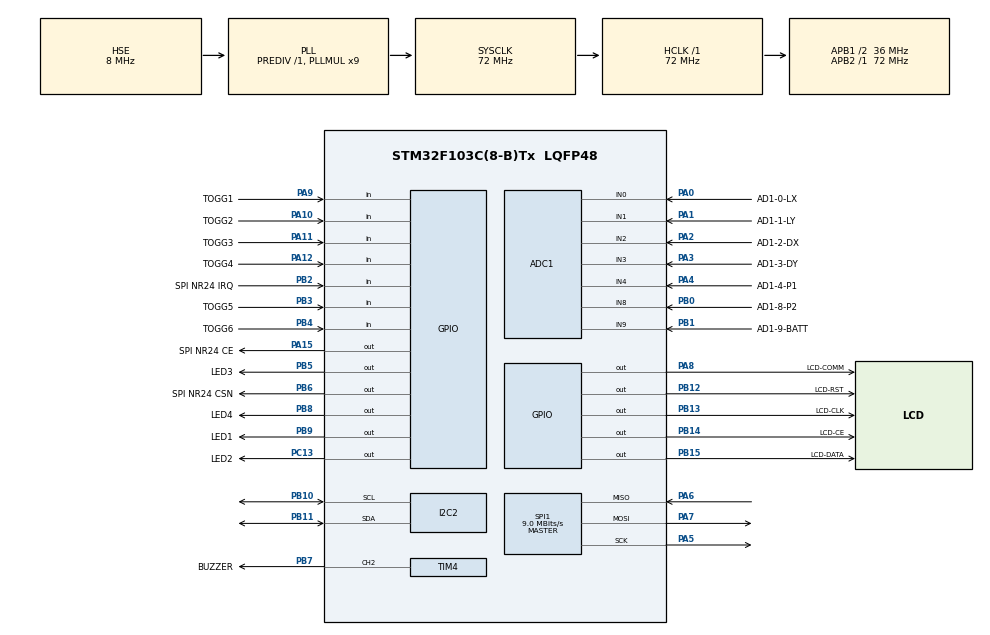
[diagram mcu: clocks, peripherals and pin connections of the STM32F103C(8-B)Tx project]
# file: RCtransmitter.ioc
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ADC1.Channel-0\#ChannelRegularConversion=ADC_CHANNEL_0
ADC1.Channel-1\#ChannelRegularConversion=ADC_CHANNEL_1
ADC1.Channel-2\#ChannelRegularConversion=ADC_CHANNEL_2
ADC1.Channel-3\#ChannelRegularConversion=ADC_CHANNEL_3
ADC1.Channel-4\#ChannelRegularConversion=ADC_CHANNEL_4
ADC1.Channel-5\#ChannelRegularConversion=ADC_CHANNEL_8
ADC1.Channel-6\#ChannelRegularConversion=ADC_CHANNEL_9
ADC1.ContinuousConvMode=ENABLE
ADC1.NbrOfConversion=7
ADC1.NbrOfConversionFlag=1
ADC1.Rank-0\#ChannelRegularConversion=1
ADC1.Rank-1\#ChannelRegularConversion=2
ADC1.Rank-2\#ChannelRegularConversion=3
ADC1.Rank-3\#ChannelRegularConversion=4
ADC1.Rank-4\#ChannelRegularConversion=5
ADC1.Rank-5\#ChannelRegularConversion=6
ADC1.Rank-6\#ChannelRegularConversion=7
ADC1.SamplingTime-0\#ChannelRegularConversion=ADC_SAMPLETIME_13CYCLES_5
ADC1.SamplingTime-1\#ChannelRegularConversion=ADC_SAMPLETIME_13CYCLES_5
ADC1.SamplingTime-2\#ChannelRegularConversion=ADC_SAMPLETIME_13CYCLES_5
ADC1.SamplingTime-3\#ChannelRegularConversion=ADC_SAMPLETIME_13CYCLES_5
ADC1.SamplingTime-4\#ChannelRegularConversion=ADC_SAMPLETIME_13CYCLES_5
ADC1.SamplingTime-5\#ChannelRegularConversion=ADC_SAMPLETIME_13CYCLES_5
ADC1.SamplingTime-6\#ChannelRegularConversion=ADC_SAMPLETIME_13CYCLES_5
ADC1.master=1
Dma.ADC1.0.Direction=DMA_PERIPH_TO_MEMORY
Dma.ADC1.0.Instance=DMA1_Channel1
Dma.ADC1.0.MemDataAlignment=DMA_MDATAALIGN_HALFWORD
Dma.ADC1.0.MemInc=DMA_MINC_ENABLE
Dma.ADC1.0.Mode=DMA_CIRCULAR
Dma.ADC1.0.PeriphDataAlignment=DMA_PDATAALIGN_HALFWORD
Dma.ADC1.0.PeriphInc=DMA_PINC_DISABLE
Dma.ADC1.0.Priority=DMA_PRIORITY_HIGH
Dma.Request0=ADC1
I2C2.I2C_Mode=I2C_Standard
Mcu.Family=STM32F1
Mcu.Name=STM32F103C(8-B)Tx
Mcu.Package=LQFP48
NVIC.DMA1_Channel1_IRQn=true\:0\:0\:false\:false\:true\:false\:true
NVIC.PriorityGroup=NVIC_PRIORITYGROUP_4
PA0-WKUP.GPIO_Label=AD1-0-LX
PA0-WKUP.Signal=ADCx_IN0
PA1.GPIO_Label=AD1-1-LY
PA1.Signal=ADCx_IN1
PA10.GPIO_Label=TOGG2
PA10.GPIO_PuPd=GPIO_PULLUP
PA10.Signal=GPIO_Input
PA11.GPIO_Label=TOGG3
PA11.GPIO_PuPd=GPIO_PULLUP
PA11.Signal=GPIO_Input
PA12.GPIO_Label=TOGG4
PA12.GPIO_PuPd=GPIO_PULLUP
PA12.Signal=GPIO_Input
PA13.Mode=Serial_Wire
PA13.Signal=SYS_JTMS-SWDIO
PA14.Mode=Serial_Wire
PA14.Signal=SYS_JTCK-SWCLK
PA15.GPIO_Label=SPI NR24 CE
PA15.Signal=GPIO_Output
PA2.GPIO_Label=AD1-2-DX
PA2.Signal=ADCx_IN2
PA3.GPIO_Label=AD1-3-DY
PA3.Signal=ADCx_IN3
PA4.GPIO_Label=AD1-4-P1
PA4.Signal=ADCx_IN4
PA5.Mode=Full_Duplex_Master
PA5.Signal=SPI1_SCK
PA6.Mode=Full_Duplex_Master
PA6.Signal=SPI1_MISO
PA7.Mode=Full_Duplex_Master
PA7.Signal=SPI1_MOSI
PA8.GPIO_Label=LCD-COMM
PA8.GPIO_Speed=GPIO_SPEED_FREQ_HIGH
PA8.Signal=GPIO_Output
PA9.GPIO_Label=TOGG1
PA9.GPIO_PuPd=GPIO_PULLUP
PA9.Signal=GPIO_Input
PB0.GPIO_Label=AD1-8-P2
PB0.Signal=ADCx_IN8
PB1.GPIO_Label=AD1-9-BATT
PB1.Signal=ADCx_IN9
PB10.Mode=I2C
PB10.Signal=I2C2_SCL
PB11.Mode=I2C
PB11.Signal=I2C2_SDA
PB12.GPIO_Label=LCD-RST
PB12.Signal=GPIO_Output
PB13.GPIO_Label=LCD-CLK
PB13.GPIO_Speed=GPIO_SPEED_FREQ_HIGH
PB13.Signal=GPIO_Output
PB14.GPIO_Label=LCD-CE
PB14.Signal=GPIO_Output
PB15.GPIO_Label=LCD-DATA
PB15.GPIO_Speed=GPIO_SPEED_FREQ_HIGH
PB15.Signal=GPIO_Output
PB2.GPIO_Label=SPI NR24 IRQ
PB2.Signal=GPIO_Input
PB3.GPIO_Label=TOGG5
PB3.GPIO_PuPd=GPIO_PULLUP
PB3.Signal=GPIO_Input
PB4.GPIO_Label=TOGG6
PB4.GPIO_PuPd=GPIO_PULLUP
PB4.Signal=GPIO_Input
PB5.GPIO_Label=LED3
PB5.Signal=GPIO_Output
PB6.GPIO_Label=SPI NR24 CSN
PB6.Signal=GPIO_Output
PB7.GPIO_Label=BUZZER
PB7.Signal=S_TIM4_CH2
PB8.GPIO_Label=LED4
PB8.Signal=GPIO_Output
PB9.GPIO_Label=LED1
PB9.Signal=GPIO_Output
PC13-TAMPER-RTC.GPIO_Label=LED2
PC13-TAMPER-RTC.Signal=GPIO_Output
PD0-OSC_IN.Mode=HSE-External-Oscillator
PD0-OSC_IN.Signal=RCC_OSC_IN
PD1-OSC_OUT.Mode=HSE-External-Oscillator
PD1-OSC_OUT.Signal=RCC_OSC_OUT
ProjectManager.HeapSize=0x200
ProjectManager.StackSize=0x400
ProjectManager.TargetToolchain=STM32CubeIDE
RCC.ADCPresc=RCC_ADCPCLK2_DIV6
RCC.AHBFreq_Value=72000000
RCC.APB1CLKDivider=RCC_HCLK_DIV2
RCC.APB1Freq_Value=36000000
RCC.APB1TimFreq_Value=72000000
RCC.APB2Freq_Value=72000000
RCC.APB2TimFreq_Value=72000000
RCC.HCLKFreq_Value=72000000
RCC.PLLMUL=RCC_PLL_MUL9
RCC.PLLSourceVirtual=RCC_PLLSOURCE_HSE
RCC.SYSCLKFreq_VALUE=72000000
RCC.SYSCLKSource=RCC_SYSCLKSOURCE_PLLCLK
RCC.USBFreq_Value=72000000
SH.ADCx_IN0.0=ADC1_IN0,IN0
SH.ADCx_IN1.0=ADC1_IN1,IN1
SH.ADCx_IN2.0=ADC1_IN2,IN2
SH.ADCx_IN3.0=ADC1_IN3,IN3
SH.ADCx_IN4.0=ADC1_IN4,IN4
SH.ADCx_IN8.0=ADC1_IN8,IN8
SH.ADCx_IN9.0=ADC1_IN9,IN9
SH.S_TIM4_CH2.0=TIM4_CH2,PWM Generation2 CH2
SPI1.BaudRatePrescaler=SPI_BAUDRATEPRESCALER_8
SPI1.CRCCalculation=SPI_CRCCALCULATION_ENABLE
SPI1.CalculateBaudRate=9.0 MBits/s
SPI1.Direction=SPI_DIRECTION_2LINES
SPI1.Mode=SPI_MODE_MASTER
SPI1.VirtualType=VM_MASTER
TIM4.Channel-PWM\ Generation2\ CH2=TIM_CHANNEL_2
TIM4.Period=5000
TIM4.Prescaler=9
TIM4.Pulse-PWM\ Generation2\ CH2=800
board=custom

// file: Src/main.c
/* USER CODE BEGIN Header */
/**
  ******************************************************************************
  * @file           : main.c
  * @brief          : Main program body
  ******************************************************************************
  * @attention
  *
  * <h2><center>&copy; Copyright (c) 2019 STMicroelectronics.
  * All rights reserved.</center></h2>
  *
  * This software component is licensed by ST under BSD 3-Clause license,
  * the "License"; You may not use this file except in compliance with the
  * License. You may obtain a copy of the License at:
  *                        opensource.org/licenses/BSD-3-Clause
  *
  ******************************************************************************
  */
/* USER CODE END Header */

#include "main.h"

/* USER CODE BEGIN Includes */
#include "nokia5110_LCD.h"
#include "nrf24.h"
#include "mcp23017.h"
#include "LCDprints.h"
/* USER CODE END Includes */

ADC_HandleTypeDef hadc1;
DMA_HandleTypeDef hdma_adc1;

I2C_HandleTypeDef hi2c2;

SPI_HandleTypeDef hspi1;

TIM_HandleTypeDef htim4;

/* USER CODE BEGIN PV */
uint32_t test1;
uint32_t test2;
uint32_t test3;
uint32_t test4;
uint32_t wifiOK;

uint32_t watch1,watch2,watch3,watch4,watch5,watch6;

char stringlcdBuffer[20];
uint16_t adcDataArray[7];

//MCP23017
MCP23017str	MCP23017DataStr;

//NRF24
uint8_t nRF24_payloadTX[32]; //TX buffer
uint8_t nRF24_payloadRX[32]; //RX buffer
const uint8_t nRF24_ADDR[3] = {5, 3, 5 }; //Address
uint8_t RXstpaketov=0;

uint32_t MainInitDoneFlag=0;
struct FlashDatastruct FlashDataDefault; //Default constant embedded in Code
struct FlashDatastruct FlashDataFlash;  //Constants read from Flash
struct FlashDatastruct FlashDataActive; //Active constants

struct DroneDataStruct DroneDataActive;
struct DroneDataStruct DroneDataFlash;
struct DroneDataStruct DroneDataTemp;
struct DroneDataStruct DroneDataInput;

float DroneTuneStep=1.0;
uint32_t DroneTuneStepInt=1;

//LCD MENUS
MenuLvL CurrentLvl;
LCDScreen CurrentScreen;
CursorPositions CurrentCursorPos;

//Buttons to move through screens, move cursor and change menu lvl
uint32_t MenuPlus,MenuMinus;
uint32_t CursorUp,CursorDown;
uint32_t ValuePlus,ValueMinus;
uint32_t LvLUp,LvlDown;

extern uint32_t CommShtdownnrf24;
extern uint8_t MSGParameterTX;
extern uint8_t MSGCommTX;

/* USER CODE END PV */

void SystemClock_Config(void);
static void MX_GPIO_Init(void);
static void MX_DMA_Init(void);
static void MX_ADC1_Init(void);
static void MX_SPI1_Init(void);
static void MX_I2C2_Init(void);
static void MX_TIM4_Init(void);

int main(void)
{
  /* USER CODE BEGIN 1 */
	//test timings DWT counter
	CoreDebug->DEMCR |= CoreDebug_DEMCR_TRCENA_Msk;
	DWT->CYCCNT = 0;
	DWT->CTRL |= 1;
  /* USER CODE END 1 */

  /* MCU Configuration--------------------------------------------------------*/

  /* Reset of all peripherals, Initializes the Flash interface and the Systick. */
  HAL_Init();

  /* Configure the system clock */
  SystemClock_Config();

  /* Initialize all configured peripherals */
  MX_GPIO_Init();
  MX_DMA_Init();
  MX_ADC1_Init();
  MX_SPI1_Init();
  MX_I2C2_Init();
  MX_TIM4_Init();
  /* USER CODE BEGIN 2 */

  HAL_ADCEx_Calibration_Start(&hadc1);
  HAL_ADC_Start_DMA(&hadc1,adcDataArray, 7);

  //DEFAULT FLASH CONSTANTS
  FlashDataDefault.controlData=CONTROLWORD;
  FlashDataDefault.LCD_contrast=0xB8;
  FlashDataDefault.LjoyXtrim=0;
  FlashDataDefault.LjoyYtrim=0;
  FlashDataDefault.RjoyXtrim=0;
  FlashDataDefault.RjoyYtrim=0;

  if( CheckFlashData(FLASHCONSTADDR) == CONTROLWORD ) //Check if any Data is present
  {
	  //Read Data and Save parameters into ACTIVE structure
	  ReadFlashData(FLASHCONSTADDR, &FlashDataActive);

  }
  else
  {
	  //Write default values into Flash, Read back data into Active Structure
	  WriteFlashData(FLASHCONSTADDR, &FlashDataDefault);
	  ReadFlashData(FLASHCONSTADDR, &FlashDataActive);
  }

  //Lightshow
  LED1ON;
  LED2ON;
  LED3ON;
  LED4ON;
  HAL_Delay(1000);
  LED1OFF;
  LED2OFF;
  LED3OFF;
  LED4OFF;

  //default LCD
  CurrentLvl=LVL0;
  CurrentScreen=MainScreen;
  CurrentCursorPos=Line0;

  //lcd init pins
  LCD_setRST(LCD_RST_GPIO_Port, LCD_RST_Pin);
  LCD_setDC(LCD_COMM_GPIO_Port, LCD_COMM_Pin);
  LCD_setCE(LCD_CE_GPIO_Port, LCD_CE_Pin);
  LCD_setDIN(LCD_DATA_GPIO_Port, LCD_DATA_Pin);
  LCD_setCLK(LCD_CLK_GPIO_Port, LCD_CLK_Pin);

  LCD_init(&FlashDataActive); //6 lines 15 characters max per line (0,0), (0,1), (0,2), (0,3), (0,4), (0,5) line starts

  //NRF24INIT
  SPI1->CR1|=SPI_CR1_SPE; //enable SPI

  nRF24_CE_L(); // RX/TX disabled

  wifiOK=nRF24_Check();

  nRF24_Init(); //Default init

  // Disable ShockBurst for all RX pipes
  nRF24_DisableAA(0xFF);

  // Set RF channel
  nRF24_SetRFChannel(15); //2400Mhz + 15Mhz

  // Set data rate
  nRF24_SetDataRate(nRF24_DR_250kbps);

  // Set CRC scheme
  nRF24_SetCRCScheme(nRF24_CRC_1byte);

  // Set address width, its common for all pipes (RX and TX)
  nRF24_SetAddrWidth(3);

  nRF24_SetAddr(nRF24_PIPE1, nRF24_ADDR); // program address for RX pipe #1
  nRF24_SetRXPipe(nRF24_PIPE1, nRF24_AA_OFF, 6); // Auto-ACK: disabled, payload length: 6 bytes

  nRF24_SetAddr(nRF24_PIPETX, nRF24_ADDR); // program TX address

  // Set TX power
  nRF24_SetTXPower(nRF24_TXPWR_18dBm);

  // Set operational mode (PTX == transmitter)
  nRF24_SetOperationalMode(nRF24_MODE_TX);

  // Clear any pending IRQ flags
  nRF24_ClearIRQFlags();

  // Wake the transceiver
  nRF24_SetPowerMode(nRF24_PWR_UP);

  //MCP23017 intit
  mcp23017_init(&hi2c2,MCP23017_ADDRESS_20);

  MainInitDoneFlag=1;

  /* USER CODE END 2 */

  /* Infinite loop */
  /* USER CODE BEGIN WHILE */
  while (1)
  {

	  if(MenuPlus)//Menu PLUS------------------------------------------------------------------------------------------------------------------------
	  {
	  	  LCD_clrScr();

	  	  switch(CurrentScreen)
	  	  {
	  	  	  case MainScreen:{CurrentScreen=MenuScreen1;}break;
	  	  	  case MenuScreen1:{CurrentScreen=TestScreen1;}break;
	  	  	  case TestScreen1:{CurrentScreen=MainScreen;}break;

	  	  	  case ButtonScreen1:{CurrentScreen=ButtonScreen2;}break;
	  	  	  case ButtonScreen2:{CurrentScreen=ButtonScreen3;}break;
	  	  	  case ButtonScreen3:{CurrentScreen=ButtonScreen1;}break;

	  	  	  case Param1TuneScreen:{CurrentScreen=Param2TuneScreen;}break;
	  	  	  case Param2TuneScreen:{CurrentScreen=Param3TuneScreen;}break;
	  	  	  case Param3TuneScreen:{CurrentScreen=Param4TuneScreen;}break;
	  	  	  case Param4TuneScreen:{CurrentScreen=Param5TuneScreen;}break;
	  	  	  case Param5TuneScreen:{CurrentScreen=Param6TuneScreen;}break;
	  	  	  case Param6TuneScreen:{CurrentScreen=Param7TuneScreen;}break;
	  	  	  case Param7TuneScreen:{CurrentScreen=Param8TuneScreen;}break;
	  	  	  case Param8TuneScreen:{CurrentScreen=Param9TuneScreen;}break;
	  	  	  case Param9TuneScreen:{CurrentScreen=Param10TuneScreen;}break;
	  	  	  case Param10TuneScreen:{CurrentScreen=Param11TuneScreen;}break;
	  	  	  case Param11TuneScreen:{CurrentScreen=Param12TuneScreen;}break;
	  	  	  case Param12TuneScreen:{CurrentScreen=Param13TuneScreen;}break;
		  	  case Param13TuneScreen:{CurrentScreen=Param14TuneScreen;}break;
		  	  case Param14TuneScreen:{CurrentScreen=Param15TuneScreen;}break;
			  case Param15TuneScreen:{CurrentScreen=Param16TuneScreen;}break;
			  case Param16TuneScreen:{CurrentScreen=Param17TuneScreen;}break;
			  case Param17TuneScreen:{CurrentScreen=Param18TuneScreen;}break;
			  case Param18TuneScreen:{CurrentScreen=Param19TuneScreen;}break;
			  case Param19TuneScreen:{CurrentScreen=Param20TuneScreen;}break;
			  case Param20TuneScreen:{CurrentScreen=Param1TuneScreen;}break;
	  	  }

		  MenuPlus=0;
		  CurrentCursorPos = Line0;//reset cursor
	  }

	  if(MenuMinus)//MENU MINUS----------------------------------------------------------------------------------------------------------------------
	  {
	  	  LCD_clrScr();

	  	  switch(CurrentScreen)
	  	  {
	  	  	  case MainScreen:{CurrentScreen=TestScreen1;}break;
	  	  	  case MenuScreen1:{CurrentScreen=MainScreen;}break;
	  	  	  case TestScreen1:{CurrentScreen=MenuScreen1;}break;

	  	  	  case ButtonScreen1:{CurrentScreen=ButtonScreen3;}break;
	  	  	  case ButtonScreen2:{CurrentScreen=ButtonScreen1;}break;
	  	  	  case ButtonScreen3:{CurrentScreen=ButtonScreen2;}break;

	  	  	  case Param1TuneScreen:{CurrentScreen=Param20TuneScreen;}break;
	  	  	  case Param2TuneScreen:{CurrentScreen=Param1TuneScreen;}break;
	  	  	  case Param3TuneScreen:{CurrentScreen=Param2TuneScreen;}break;
	  	  	  case Param4TuneScreen:{CurrentScreen=Param3TuneScreen;}break;
	  	  	  case Param5TuneScreen:{CurrentScreen=Param4TuneScreen;}break;
	  	  	  case Param6TuneScreen:{CurrentScreen=Param5TuneScreen;}break;
	  	  	  case Param7TuneScreen:{CurrentScreen=Param6TuneScreen;}break;
	  	  	  case Param8TuneScreen:{CurrentScreen=Param7TuneScreen;}break;
	  	  	  case Param9TuneScreen:{CurrentScreen=Param8TuneScreen;}break;
	  	  	  case Param10TuneScreen:{CurrentScreen=Param9TuneScreen;}break;
	  	  	  case Param11TuneScreen:{CurrentScreen=Param10TuneScreen;}break;
	  	  	  case Param12TuneScreen:{CurrentScreen=Param11TuneScreen;}break;
		  	  case Param13TuneScreen:{CurrentScreen=Param12TuneScreen;}break;
		  	  case Param14TuneScreen:{CurrentScreen=Param13TuneScreen;}break;
			  case Param15TuneScreen:{CurrentScreen=Param14TuneScreen;}break;
			  case Param16TuneScreen:{CurrentScreen=Param15TuneScreen;}break;
			  case Param17TuneScreen:{CurrentScreen=Param16TuneScreen;}break;
			  case Param18TuneScreen:{CurrentScreen=Param17TuneScreen;}break;
			  case Param19TuneScreen:{CurrentScreen=Param18TuneScreen;}break;
			  case Param20TuneScreen:{CurrentScreen=Param19TuneScreen;}break;
	  	  }

		  MenuMinus=0;
		  CurrentCursorPos = Line0;//reset cursor
	  }

	  if(LvLUp)//LVL UP------------------------------------------------------------------------------------------------------------------------------
	  {
		  LCD_clrScr();

          switch(CurrentScreen)
          {
              case MenuScreen1:
              {
            	  switch(CurrentCursorPos)
            	  {
                  	  case Line0:{CurrentScreen=MSGScreen1;}break;
                  	  case Line1:{CurrentScreen=ButtonScreen1;}break;

                  	  case Line2:{
                  		  	  	  	  CurrentScreen=FlashDataScreenRd;
                  		  	  	  	  ReadFlashData(FLASHCONSTADDR, &FlashDataFlash);
                  	  	  	  	  }break;

                  	  case Line3:{
                  		  	  	  	  CurrentScreen=FlashDataScreenWr;

                  	  	  	  	 }break;

                  	  case Line4:{CurrentScreen=CommandScreen1;}break;

                  	  case Line5:{CurrentScreen=Param1TuneScreen;}break;
            	  }
              }break;

              case CommandScreen1:
              {
            	  switch(CurrentCursorPos)
            	  {
                  	  case Line0:{CommShtdownnrf24=!CommShtdownnrf24;}break;
                  	  case Line1:{WriteFlashData(FLASHCONSTADDR, &FlashDataActive);}break;
                  	  case Line2:{EraseFlashData(FLASHCONSTADDR);}break;
                  	  case Line3:{MSGCommTX=COMMWRITEFLASHDR;}break;
                  	  case Line4:{MSGCommTX=COMMERASEFLASHDR;}break;
            	  }
              }break;

              case Param1TuneScreen:{
            	  	  	  	  	  	  if(CurrentCursorPos==Line2){MSGParameterTX=PARAM1;MSGCommTX=COMMPARAMFLASH;}
              	  	  	  	  	  	}break;
              case Param2TuneScreen:{
            	  	  	  	  	  	  if(CurrentCursorPos==Line2){MSGParameterTX=PARAM2;MSGCommTX=COMMPARAMFLASH;}
              	  	  	  	  	  	}break;
              case Param3TuneScreen:{
            	  	  	  	  	  	  if(CurrentCursorPos==Line2){MSGParameterTX=PARAM3;MSGCommTX=COMMPARAMFLASH;}
              	  	  	  	  	  	}break;
              case Param4TuneScreen:{
            	  	  	  	  	  	  if(CurrentCursorPos==Line2){MSGParameterTX=PARAM4;MSGCommTX=COMMPARAMFLASH;}
              	  	  	  	  	  	}break;
              case Param5TuneScreen:{
            	  	  	  	  	  	  if(CurrentCursorPos==Line2){MSGParameterTX=PARAM5;MSGCommTX=COMMPARAMFLASH;}
              	  	  	  	  	  	}break;
              case Param6TuneScreen:{
            	  	  	  	  	  	  if(CurrentCursorPos==Line2){MSGParameterTX=PARAM6;MSGCommTX=COMMPARAMFLASH;}
              	  	  	  	  	  	}break;
              case Param7TuneScreen:{
            	  	  	  	  	  	  if(CurrentCursorPos==Line2){MSGParameterTX=PARAM7;MSGCommTX=COMMPARAMFLASH;}
              	  	  	  	  	  	}break;
              case Param8TuneScreen:{
            	  	  	  	  	  	  if(CurrentCursorPos==Line2){MSGParameterTX=PARAM8;MSGCommTX=COMMPARAMFLASH;}
              	  	  	  	  	  	}break;
              case Param9TuneScreen:{
            	  	  	  	  	  	  if(CurrentCursorPos==Line2){MSGParameterTX=PARAM9;MSGCommTX=COMMPARAMFLASH;}
              	  	  	  	  	  	}break;
              case Param10TuneScreen:{
            	  	  	  	  	  	  if(CurrentCursorPos==Line2){MSGParameterTX=PARAM10;MSGCommTX=COMMPARAMFLASH;}
              	  	  	  	  	  	}break;
              case Param11TuneScreen:{
            	  	  	  	  	  	  if(CurrentCursorPos==Line2){MSGParameterTX=PARAM11;MSGCommTX=COMMPARAMFLASH;}
              	  	  	  	  	  	}break;
              case Param12TuneScreen:{
            	  	  	  	  	  	  if(CurrentCursorPos==Line2){MSGParameterTX=PARAM12;MSGCommTX=COMMPARAMFLASH;}
              	  	  	  	  	  	}break;
              case Param13TuneScreen:{
            	  	  	  	  	  	  if(CurrentCursorPos==Line2){MSGParameterTX=PARAM13;MSGCommTX=COMMPARAMFLASH;}
              	  	  	  	  	  	}break;
              case Param14TuneScreen:{
            	  	  	  	  	  	  if(CurrentCursorPos==Line2){MSGParameterTX=PARAM14;MSGCommTX=COMMPARAMFLASH;}
              	  	  	  	  	  	}break;
              case Param15TuneScreen:{
            	  	  	  	  	  	  if(CurrentCursorPos==Line2){MSGParameterTX=PARAM15;MSGCommTX=COMMPARAMFLASH;}
              	  	  	  	  	  	}break;
              case Param16TuneScreen:{
            	  	  	  	  	  	  if(CurrentCursorPos==Line2){MSGParameterTX=PARAM16;MSGCommTX=COMMPARAMFLASH;}
              	  	  	  	  	  	}break;
              case Param17TuneScreen:{
            	  	  	  	  	  	  if(CurrentCursorPos==Line2){MSGParameterTX=PARAM17;MSGCommTX=COMMPARAMFLASH;}
              	  	  	  	  	  	}break;
              case Param18TuneScreen:{
            	  	  	  	  	  	  if(CurrentCursorPos==Line2){MSGParameterTX=PARAM18;MSGCommTX=COMMPARAMFLASH;}
              	  	  	  	  	  	}break;
              case Param19TuneScreen:{
            	  	  	  	  	  	  if(CurrentCursorPos==Line2){MSGParameterTX=PARAM19;MSGCommTX=COMMPARAMFLASH;}
              	  	  	  	  	  	}break;
              case Param20TuneScreen:{
            	  	  	  	  	  	  if(CurrentCursorPos==Line2){MSGParameterTX=PARAM20;MSGCommTX=COMMPARAMFLASH;}
              	  	  	  	  	  	}break;
          }
		  LvLUp=0;
		  CurrentCursorPos = Line0;//reset cursor
	  }

	  if(LvlDown)//LVL DOWN---------------------------------------------------------------------------------------------------------------------------
	  {
		  LCD_clrScr();

		  switch(CurrentScreen)
		  {
		      case MenuScreen1:{CurrentScreen=MainScreen;}break;
		      case TestScreen1:{CurrentScreen=MainScreen;}break;

		      case MSGScreen1:{CurrentScreen=MenuScreen1;}break;
		      case ButtonScreen1:{CurrentScreen=MenuScreen1;}break;
		      case ButtonScreen2:{CurrentScreen=MenuScreen1;}break;
		      case ButtonScreen3:{CurrentScreen=MenuScreen1;}break;
		      case FlashDataScreenRd:{CurrentScreen=MenuScreen1;}break;
		      case FlashDataScreenWr:{CurrentScreen=MenuScreen1;}break;
		      case CommandScreen1:{CurrentScreen=MenuScreen1;}break;
	  	  	  case Param1TuneScreen:{CurrentScreen=MenuScreen1;}break;
	  	  	  case Param2TuneScreen:{CurrentScreen=MenuScreen1;}break;
	  	  	  case Param3TuneScreen:{CurrentScreen=MenuScreen1;}break;
	  	  	  case Param4TuneScreen:{CurrentScreen=MenuScreen1;}break;
	  	  	  case Param5TuneScreen:{CurrentScreen=MenuScreen1;}break;
	  	  	  case Param6TuneScreen:{CurrentScreen=MenuScreen1;}break;
	  	  	  case Param7TuneScreen:{CurrentScreen=MenuScreen1;}break;
	  	  	  case Param8TuneScreen:{CurrentScreen=MenuScreen1;}break;
	  	  	  case Param9TuneScreen:{CurrentScreen=MenuScreen1;}break;
	  	  	  case Param10TuneScreen:{CurrentScreen=MenuScreen1;}break;
	  	  	  case Param11TuneScreen:{CurrentScreen=MenuScreen1;}break;
	  	  	  case Param12TuneScreen:{CurrentScreen=MenuScreen1;}break;
		  	  case Param13TuneScreen:{CurrentScreen=MenuScreen1;}break;
		  	  case Param14TuneScreen:{CurrentScreen=MenuScreen1;}break;
			  case Param15TuneScreen:{CurrentScreen=MenuScreen1;}break;
			  case Param16TuneScreen:{CurrentScreen=MenuScreen1;}break;
			  case Param17TuneScreen:{CurrentScreen=MenuScreen1;}break;
			  case Param18TuneScreen:{CurrentScreen=MenuScreen1;}break;
			  case Param19TuneScreen:{CurrentScreen=MenuScreen1;}break;
			  case Param20TuneScreen:{CurrentScreen=MenuScreen1;}break;
		  }
		  LvlDown=0;
		  CurrentCursorPos = Line0;//reset cursor
	  }

	  if(CursorUp)//Cursor Up-------------------------------------------------------------------------------------------------------------------------
	  {
		  if(CurrentCursorPos == Line0)CurrentCursorPos=Line5;
		  else CurrentCursorPos--;

		  CursorUp=0;
	  }

	  if(CursorDown)//Cursor Down---------------------------------------------------------------------------------------------------------------------
	  {
		  if(CurrentCursorPos == Line5)CurrentCursorPos=Line0;
		  else CurrentCursorPos++;

		  CursorDown=0;
	  }

	  if(ValuePlus)//Value Plus---------------------------------------------------------------------------------------------------------------------
	  {

		  switch(CurrentScreen)
		  {
		  	  case FlashDataScreenWr:
		  	  {
		  		switch(CurrentCursorPos)
		  		{
		  			case Line0:{FlashDataActive.controlData++;};break;
		  			case Line1:{FlashDataActive.LCD_contrast+=1;};break;
		  			case Line2:{};break;
		  			case Line3:{};break;
		  			case Line4:{};break;
		  			case Line5:{};break;
		  		}
		  	  }break;

			  case Param1TuneScreen:{
				  	  	  	  	  	  if(CurrentCursorPos!=Line1)
				  	  	  	  	  	  {
				  	  	  	  	  		  DroneDataInput.pid_p_gain_pitch+=DroneTuneStep;
					  	  	  	  	  	  if(DroneDataInput.pid_p_gain_pitch > MAXREGPARAM )DroneDataInput.pid_p_gain_pitch=MAXREGPARAM;

					  	  	  	  	  	  MSGCommTX=COMMPARAMACTIVE;
					  	  	  	  	  	  MSGParameterTX=PARAM1;
				  	  	  	  	  	  }
				  	  	  	  	  	  else DroneTuneStep*=10;

			  	  	  	  	  	  	}break;
			  case Param2TuneScreen:{
				  	  	  	  	  	  if(CurrentCursorPos!=Line1)
				  	  	  	  	  	  {
				  	  	  	  	  		  DroneDataInput.pid_i_gain_pitch+=DroneTuneStep;
				  	  	  	  	  		  if(DroneDataInput.pid_i_gain_pitch > MAXREGPARAM)DroneDataInput.pid_i_gain_pitch=MAXREGPARAM;

				  	  	  	  	  		  MSGCommTX=COMMPARAMACTIVE;
				  	  	  	  	  		  MSGParameterTX=PARAM2;
				  	  	  	  	  	  }
				  	  	  	  	  	  else DroneTuneStep*=10;

			  	  	  	  	  	  	}break;
			  case Param3TuneScreen:{
				  	  	  	  	  	  if(CurrentCursorPos!=Line1)
				  	  	  	  	  	  {
				  	  	  	  	  		  DroneDataInput.pid_d_gain_pitch+=DroneTuneStep;
				  	  	  	  	  		  if(DroneDataInput.pid_d_gain_pitch > MAXREGPARAM)DroneDataInput.pid_d_gain_pitch=MAXREGPARAM;

				  	  	  	  	  		  MSGCommTX=COMMPARAMACTIVE;
				  	  	  	  	  		  MSGParameterTX=PARAM3;
				  	  	  	  	  	  }
				  	  	  	  	  	  else DroneTuneStep*=10;

			  	  	  	  	  	  	}break;
			  case Param4TuneScreen:{
				  	  	  	  	  	  if(CurrentCursorPos!=Line1)
				  	  	  	  	  	  {
				  	  	  	  	  		  DroneDataInput.pid_p_gain_roll+=DroneTuneStep;
				  	  	  	  	  		  if(DroneDataInput.pid_p_gain_roll > MAXREGPARAM)DroneDataInput.pid_p_gain_roll=MAXREGPARAM;

				  	  	  	  	  		  MSGCommTX=COMMPARAMACTIVE;
				  	  	  	  	  		  MSGParameterTX=PARAM4;
				  	  	  	  	  	  }
				  	  	  	  	  	  else DroneTuneStep*=10;

			  	  	  	  	  	  	}break;
			  case Param5TuneScreen:{
				  	  	  	  	  	  if(CurrentCursorPos!=Line1)
				  	  	  	  	  	  {
				  	  	  	  	  		  DroneDataInput.pid_i_gain_roll+=DroneTuneStep;
				  	  	  	  	  		  if(DroneDataInput.pid_i_gain_roll > MAXREGPARAM)DroneDataInput.pid_i_gain_roll=MAXREGPARAM;

					  	  	  	  	  	  MSGCommTX=COMMPARAMACTIVE;
					  	  	  	  	  	  MSGParameterTX=PARAM5;
				  	  	  	  	  	  }
				  	  	  	  	  	  else DroneTuneStep*=10;

			  	  	  	  	  	  	}break;
			  case Param6TuneScreen:{
				  	  	  	  	  	  if(CurrentCursorPos!=Line1)
				  	  	  	  	  	  {
				  	  	  	  	  		  DroneDataInput.pid_d_gain_roll+=DroneTuneStep;
				  	  	  	  	  		  if(DroneDataInput.pid_d_gain_roll > MAXREGPARAM)DroneDataInput.pid_d_gain_roll=MAXREGPARAM;

				  	  	  	  	  		  MSGCommTX=COMMPARAMACTIVE;
				  	  	  	  	  		  MSGParameterTX=PARAM6;
				  	  	  	  	  	  }
				  	  	  	  	  	  else DroneTuneStep*=10;

			  	  	  	  	  	  	}break;
			  case Param7TuneScreen:{
				  	  	  	  	  	  if(CurrentCursorPos!=Line1)
				  	  	  	  	  	  {
				  	  	  	  	  		  DroneDataInput.pid_p_gain_yaw+=DroneTuneStep;
				  	  	  	  	  		  if(DroneDataInput.pid_p_gain_yaw > MAXREGPARAM)DroneDataInput.pid_p_gain_yaw=MAXREGPARAM;

				  	  	  	  	  		  MSGCommTX=COMMPARAMACTIVE;
				  	  	  	  	  		  MSGParameterTX=PARAM7;
				  	  	  	  	  	  }
				  	  	  	  	  	  else DroneTuneStep*=10;

			  	  	  	  	  	  	}break;
			  case Param8TuneScreen:{
				  	  	  	  	  	  if(CurrentCursorPos!=Line1)
				  	  	  	  	  	  {
				  	  	  	  	  		  DroneDataInput.pid_i_gain_yaw+=DroneTuneStep;
				  	  	  	  	  		  if(DroneDataInput.pid_i_gain_yaw > MAXREGPARAM)DroneDataInput.pid_i_gain_yaw=MAXREGPARAM;

					  	  	  	  	  	  MSGCommTX=COMMPARAMACTIVE;
					  	  	  	  	  	  MSGParameterTX=PARAM8;
				  	  	  	  	  	  }
				  	  	  	  	  	  else DroneTuneStep*=10;

			  	  	  	  	  	  	}break;
			  case Param9TuneScreen:{
				  	  	  	  	  	  if(CurrentCursorPos!=Line1)
				  	  	  	  	  	  {
				  	  	  	  	  		  DroneDataInput.pid_d_gain_yaw+=DroneTuneStep;
				  	  	  	  	  		  if(DroneDataInput.pid_d_gain_yaw > MAXREGPARAM)DroneDataInput.pid_d_gain_yaw=MAXREGPARAM;

				  	  	  	  	  		  MSGCommTX=COMMPARAMACTIVE;
				  	  	  	  	  		  MSGParameterTX=PARAM9;
				  	  	  	  	  	  }
				  	  	  	  	  	  else DroneTuneStep*=10;

			  	  	  	  	  	  	}break;
			  case Param10TuneScreen:{
				  	  	  	  	  	  if(CurrentCursorPos!=Line1)
				  	  	  	  	  	  {
				  	  	  	  	  		  DroneDataInput.pid_max_pitch+=DroneTuneStepInt;
				  	  	  	  	  		  if(DroneDataInput.pid_max_pitch > MAXPIDPARAM)DroneDataInput.pid_max_pitch=MAXPIDPARAM;

				  	  	  	  	  		  MSGCommTX=COMMPARAMACTIVE;
				  	  	  	  	  		  MSGParameterTX=PARAM10;
				  	  	  	  	  	  }
				  	  	  	  	  	  else DroneTuneStepInt*=10;

			  	  	  	  	  	  	 }break;
			  case Param11TuneScreen:{
				  	  	  	  	  	  if(CurrentCursorPos!=Line1)
				  	  	  	  	  	  {
				  	  	  	  	  		  DroneDataInput.pid_i_max_pitch+=DroneTuneStepInt;
				  	  	  	  	  		  if(DroneDataInput.pid_i_max_pitch > MAXPIDPARAM)DroneDataInput.pid_i_max_pitch=MAXPIDPARAM;

				  	  	  	  	  		  MSGCommTX=COMMPARAMACTIVE;
				  	  	  	  	  		  MSGParameterTX=PARAM11;
				  	  	  	  	  	  }
				  	  	  	  	  	  else DroneTuneStepInt*=10;

			  	  	  	  	  	  	 }break;
			  case Param12TuneScreen:{
				  	  	  	  	  	  if(CurrentCursorPos!=Line1)
				  	  	  	  	  	  {
				  	  	  	  	  		  DroneDataInput.pid_max_roll+=DroneTuneStepInt;
				  	  	  	  	  		  if(DroneDataInput.pid_max_roll > MAXPIDPARAM)DroneDataInput.pid_max_roll=MAXPIDPARAM;

				  	  	  	  	  		  MSGCommTX=COMMPARAMACTIVE;
				  	  	  	  	  		  MSGParameterTX=PARAM12;
				  	  	  	  	  	  }
				  	  	  	  	  	  else DroneTuneStepInt*=10;

			  	  	  	  	  	  	 }break;
			  case Param13TuneScreen:{
				  	  	  	  	  	  if(CurrentCursorPos!=Line1)
				  	  	  	  	  	  {
				  	  	  	  	  		  DroneDataInput.pid_i_max_roll+=DroneTuneStepInt;
				  	  	  	  	  		  if(DroneDataInput.pid_i_max_roll > MAXPIDPARAM)DroneDataInput.pid_i_max_roll=MAXPIDPARAM;

				  	  	  	  	  		  MSGCommTX=COMMPARAMACTIVE;
				  	  	  	  	  		  MSGParameterTX=PARAM13;
				  	  	  	  	  	  }
				  	  	  	  	  	  else DroneTuneStepInt*=10;

			  	  	  	  	  	  	 }break;
			  case Param14TuneScreen:{
				  	  	  	  	  	  if(CurrentCursorPos!=Line1)
				  	  	  	  	  	  {
				  	  	  	  	  		  DroneDataInput.pid_max_yaw+=DroneTuneStepInt;
				  	  	  	  	  		  if(DroneDataInput.pid_max_yaw > MAXPIDPARAM)DroneDataInput.pid_max_yaw=MAXPIDPARAM;

				  	  	  	  	  		  MSGCommTX=COMMPARAMACTIVE;
				  	  	  	  	  		  MSGParameterTX=PARAM14;
				  	  	  	  	  	  }
				  	  	  	  	  	  else DroneTuneStepInt*=10;

			  	  	  	  	  	  	 }break;
			  case Param15TuneScreen:{
				  	  	  	  	  	  if(CurrentCursorPos!=Line1)
				  	  	  	  	  	  {
				  	  	  	  	  		  DroneDataInput.pid_i_max_yaw+=DroneTuneStepInt;
				  	  	  	  	  		  if(DroneDataInput.pid_i_max_yaw > MAXPIDPARAM)DroneDataInput.pid_i_max_yaw=MAXPIDPARAM;

				  	  	  	  	  		  MSGCommTX=COMMPARAMACTIVE;
				  	  	  	  	  		  MSGParameterTX=PARAM15;
				  	  	  	  	  	  }
				  	  	  	  	  	  else DroneTuneStepInt*=10;

			  	  	  	  	  	  	 }break;
			  case Param16TuneScreen:{
				  	  	  	  	  	  if(CurrentCursorPos!=Line1)
				  	  	  	  	  	  {
				  	  	  	  	  		  DroneDataInput.maxpitchdegree+=DroneTuneStepInt;
				  	  	  	  	  		  if(DroneDataInput.maxpitchdegree > MAXDEGREEPARAM)DroneDataInput.maxpitchdegree=MAXDEGREEPARAM;

				  	  	  	  	  		  MSGCommTX=COMMPARAMACTIVE;
				  	  	  	  	  		  MSGParameterTX=PARAM16;
				  	  	  	  	  	  }
				  	  	  	  	  	  else DroneTuneStepInt*=10;

			  	  	  	  	  	  	 }break;
			  case Param17TuneScreen:{
				  	  	  	  	  	  if(CurrentCursorPos!=Line1)
				  	  	  	  	  	  {
				  	  	  	  	  		  DroneDataInput.maxrolldegree+=DroneTuneStepInt;
				  	  	  	  	  		  if(DroneDataInput.maxrolldegree > MAXDEGREEPARAM)DroneDataInput.maxrolldegree=MAXDEGREEPARAM;

					  	  	  	  	  	  MSGCommTX=COMMPARAMACTIVE;
					  	  	  	  	  	  MSGParameterTX=PARAM17;
				  	  	  	  	  	  }
				  	  	  	  	  	  else DroneTuneStepInt*=10;

			  	  	  	  	  	  	 }break;
			  case Param18TuneScreen:{
				  	  	  	  	  	  if(CurrentCursorPos!=Line1)
				  	  	  	  	  	  {
				  	  	  	  	  		  DroneDataInput.maxyawdegree+=DroneTuneStepInt;
				  	  	  	  	  		  if(DroneDataInput.maxyawdegree > MAXDEGREEPARAM)DroneDataInput.maxyawdegree=MAXDEGREEPARAM;

				  	  	  	  	  		  MSGCommTX=COMMPARAMACTIVE;
				  	  	  	  	  		  MSGParameterTX=PARAM18;
				  	  	  	  	  	  }
				  	  	  	  	  	  else DroneTuneStepInt*=10;

			  	  	  	  	  	  	 }break;
			  case Param19TuneScreen:{
				  	  	  	  	  	  if(CurrentCursorPos!=Line1)
				  	  	  	  	  	  {
				  	  	  	  	  		  DroneDataInput.minthrottle+=DroneTuneStepInt;
				  	  	  	  	  		  if(DroneDataInput.minthrottle > MAXTHROTTLE)DroneDataInput.minthrottle=MAXTHROTTLE;

				  	  	  	  	  		  MSGCommTX=COMMPARAMACTIVE;
				  	  	  	  	  		  MSGParameterTX=PARAM19;
				  	  	  	  	  	  }
				  	  	  	  	  	  else DroneTuneStepInt*=10;

			  	  	  	  	  	  	 }break;
			  case Param20TuneScreen:{
				  	  	  	  	  	  if(CurrentCursorPos!=Line1)
				  	  	  	  	  	  {
				  	  	  	  	  		  DroneDataInput.maxthrottle+=DroneTuneStepInt;
				  	  	  	  	  		  if(DroneDataInput.maxthrottle > MAXTHROTTLE)DroneDataInput.maxthrottle=MAXTHROTTLE;

				  	  	  	  	  		  MSGCommTX=COMMPARAMACTIVE;
				  	  	  	  	  		  MSGParameterTX=PARAM20;
				  	  	  	  	  	  }
				  	  	  	  	  	  else DroneTuneStepInt*=10;

			  	  	  	  	  	     }break;
		  }
		  //zasicenje tunning step
		  if(DroneTuneStep>DRONETUNESTEPMAX)DroneTuneStep=DRONETUNESTEPMAX;
		  if(DroneTuneStep<DRONETUNESTEPMIN)DroneTuneStep=DRONETUNESTEPMIN;

		  if(DroneTuneStepInt>DRONETUNESTEPINTMAX)DroneTuneStepInt=DRONETUNESTEPINTMAX;
		  if(DroneTuneStepInt<DRONETUNESTEPINTMIN)DroneTuneStepInt=DRONETUNESTEPINTMIN;

		  ValuePlus=0;
	  }

	  if(ValueMinus)//Value Minus---------------------------------------------------------------------------------------------------------------------
	  {

		  switch(CurrentScreen)
		  {
		  	  case FlashDataScreenWr:
		  	  {
		  		switch(CurrentCursorPos)
		  		{
		  			case Line0:{FlashDataActive.controlData--;};break;
		  			case Line1:{FlashDataActive.LCD_contrast-=1;};break;
		  			case Line2:{};break;
		  			case Line3:{};break;
		  			case Line4:{};break;
		  			case Line5:{};break;
		  		}
		  	  }break;

			  case Param1TuneScreen:{
				  	  	  	  	  	  if(CurrentCursorPos!=Line1)
				  	  	  	  	  	  {
				  	  	  	  	  		  DroneDataInput.pid_p_gain_pitch-=DroneTuneStep;
				  	  	  	  	  		  if(DroneDataInput.pid_p_gain_pitch < MINREGPARAM )DroneDataInput.pid_p_gain_pitch=MINREGPARAM;

				  	  	  	  	  		  MSGCommTX=COMMPARAMACTIVE;
				  	  	  	  	  		  MSGParameterTX=PARAM1;
				  	  	  	  	  	  }
				  	  	  	  	  	  else DroneTuneStep/=10;

			  	  	  	  	  	  	}break;
			  case Param2TuneScreen:{
				  	  	  	  	  	  if(CurrentCursorPos!=Line1)
				  	  	  	  	  	  {
				  	  	  	  	  		  DroneDataInput.pid_i_gain_pitch-=DroneTuneStep;
				  	  	  	  	  		  if(DroneDataInput.pid_i_gain_pitch < MINREGPARAM)DroneDataInput.pid_i_gain_pitch=MINREGPARAM;

					  	  	  	  	  	  MSGCommTX=COMMPARAMACTIVE;
					  	  	  	  	  	  MSGParameterTX=PARAM2;
				  	  	  	  	  	  }
				  	  	  	  	  	  else DroneTuneStep/=10;

			  	  	  	  	  	  	}break;
			  case Param3TuneScreen:{
				  	  	  	  	  	  if(CurrentCursorPos!=Line1)
				  	  	  	  	  	  {
				  	  	  	  	  		  DroneDataInput.pid_d_gain_pitch-=DroneTuneStep;
				  	  	  	  	  		  if(DroneDataInput.pid_d_gain_pitch < MINREGPARAM)DroneDataInput.pid_d_gain_pitch=MINREGPARAM;

					  	  	  	  	  	  MSGCommTX=COMMPARAMACTIVE;
					  	  	  	  	  	  MSGParameterTX=PARAM3;
				  	  	  	  	  	  }
				  	  	  	  	  	  else DroneTuneStep/=10;

			  	  	  	  	  	  	}break;
			  case Param4TuneScreen:{
				  	  	  	  	  	  if(CurrentCursorPos!=Line1)
				  	  	  	  	  	  {
				  	  	  	  	  		  DroneDataInput.pid_p_gain_roll-=DroneTuneStep;
				  	  	  	  	  		  if(DroneDataInput.pid_p_gain_roll < MINREGPARAM)DroneDataInput.pid_p_gain_roll=MINREGPARAM;

				  	  	  	  	  		  MSGCommTX=COMMPARAMACTIVE;
				  	  	  	  	  		  MSGParameterTX=PARAM4;
				  	  	  	  	  	  }
				  	  	  	  	  	  else DroneTuneStep/=10;

			  	  	  	  	  	  	}break;
			  case Param5TuneScreen:{
				  	  	  	  	  	  if(CurrentCursorPos!=Line1)
				  	  	  	  	  	  {
				  	  	  	  	  		  DroneDataInput.pid_i_gain_roll-=DroneTuneStep;
				  	  	  	  	  		  if(DroneDataInput.pid_i_gain_roll < MINREGPARAM)DroneDataInput.pid_i_gain_roll=MINREGPARAM;

				  	  	  	  	  		  MSGCommTX=COMMPARAMACTIVE;
				  	  	  	  	  		  MSGParameterTX=PARAM5;
				  	  	  	  	  	  }
				  	  	  	  	  	  else DroneTuneStep/=10;

			  	  	  	  	  	  	}break;
			  case Param6TuneScreen:{
				  	  	  	  	  	  if(CurrentCursorPos!=Line1)
				  	  	  	  	  	  {
				  	  	  	  	  		  DroneDataInput.pid_d_gain_roll-=DroneTuneStep;
				  	  	  	  	  		  if(DroneDataInput.pid_d_gain_roll < MINREGPARAM)DroneDataInput.pid_d_gain_roll=MINREGPARAM;

					  	  	  	  	  	  MSGCommTX=COMMPARAMACTIVE;
					  	  	  	  	  	  MSGParameterTX=PARAM6;
				  	  	  	  	  	  }
				  	  	  	  	  	  else DroneTuneStep/=10;

			  	  	  	  	  	  	}break;
			  case Param7TuneScreen:{
				  	  	  	  	  	  if(CurrentCursorPos!=Line1)
				  	  	  	  	  	  {
				  	  	  	  	  		  DroneDataInput.pid_p_gain_yaw-=DroneTuneStep;
				  	  	  	  	  		  if(DroneDataInput.pid_p_gain_yaw < MINREGPARAM)DroneDataInput.pid_p_gain_yaw=MINREGPARAM;

				  	  	  	  	  		  MSGCommTX=COMMPARAMACTIVE;
				  	  	  	  	  		  MSGParameterTX=PARAM7;
				  	  	  	  	  	  }
				  	  	  	  	  	  else DroneTuneStep/=10;

			  	  	  	  	  	  	}break;
			  case Param8TuneScreen:{
				  	  	  	  	  	  if(CurrentCursorPos!=Line1)
				  	  	  	  	  	  {
				  	  	  	  	  		  DroneDataInput.pid_i_gain_yaw-=DroneTuneStep;
				  	  	  	  	  		  if(DroneDataInput.pid_i_gain_yaw < MINREGPARAM)DroneDataInput.pid_i_gain_yaw=MINREGPARAM;

				  	  	  	  	  		  MSGCommTX=COMMPARAMACTIVE;
				  	  	  	  	  		  MSGParameterTX=PARAM8;
				  	  	  	  	  	  }
				  	  	  	  	  	  else DroneTuneStep/=10;

			  	  	  	  	  	  	}break;
			  case Param9TuneScreen:{
				  	  	  	  	  	  if(CurrentCursorPos!=Line1)
				  	  	  	  	  	  {
				  	  	  	  	  		  DroneDataInput.pid_d_gain_yaw-=DroneTuneStep;
				  	  	  	  	  		  if(DroneDataInput.pid_d_gain_yaw < MINREGPARAM)DroneDataInput.pid_d_gain_yaw=MINREGPARAM;

				  	  	  	  	  		  MSGCommTX=COMMPARAMACTIVE;
				  	  	  	  	  		  MSGParameterTX=PARAM9;
				  	  	  	  	  	  }
				  	  	  	  	  	  else DroneTuneStep/=10;

			  	  	  	  	  	  	}break;
			  case Param10TuneScreen:{
				  	  	  	  	  	  if(CurrentCursorPos!=Line1)
				  	  	  	  	  	  {
				  	  	  	  	  		  DroneDataInput.pid_max_pitch-=DroneTuneStepInt;
				  	  	  	  	  		  if(DroneDataInput.pid_max_pitch < MINPIDPARAM)DroneDataInput.pid_max_pitch=MINPIDPARAM;

				  	  	  	  	  		  MSGCommTX=COMMPARAMACTIVE;
				  	  	  	  	  		  MSGParameterTX=PARAM10;
				  	  	  	  	  	  }
				  	  	  	  	  	  else DroneTuneStepInt/=10;

			  	  	  	  	  	  	 }break;
			  case Param11TuneScreen:{
				  	  	  	  	  	  if(CurrentCursorPos!=Line1)
				  	  	  	  	  	  {
				  	  	  	  	  		  DroneDataInput.pid_i_max_pitch-=DroneTuneStepInt;
				  	  	  	  	  		  if(DroneDataInput.pid_i_max_pitch < MINPIDPARAM)DroneDataInput.pid_i_max_pitch=MINPIDPARAM;

				  	  	  	  	  		  MSGCommTX=COMMPARAMACTIVE;
				  	  	  	  	  		  MSGParameterTX=PARAM11;
				  	  	  	  	  	  }
				  	  	  	  	  	  else DroneTuneStepInt/=10;

			  	  	  	  	  	  	 }break;
			  case Param12TuneScreen:{
				  	  	  	  	  	  if(CurrentCursorPos!=Line1)
				  	  	  	  	  	  {
				  	  	  	  	  		  DroneDataInput.pid_max_roll-=DroneTuneStepInt;
				  	  	  	  	  		  if(DroneDataInput.pid_max_roll < MINPIDPARAM)DroneDataInput.pid_max_roll=MINPIDPARAM;

				  	  	  	  	  		  MSGCommTX=COMMPARAMACTIVE;
				  	  	  	  	  		  MSGParameterTX=PARAM12;
				  	  	  	  	  	  }
				  	  	  	  	  	  else DroneTuneStepInt/=10;

			  	  	  	  	  	  	 }break;
			  case Param13TuneScreen:{
				  	  	  	  	  	  if(CurrentCursorPos!=Line1)
				  	  	  	  	  	  {
				  	  	  	  	  		  DroneDataInput.pid_i_max_roll-=DroneTuneStepInt;
				  	  	  	  	  		  if(DroneDataInput.pid_i_max_roll < MINPIDPARAM)DroneDataInput.pid_i_max_roll=MINPIDPARAM;

				  	  	  	  	  		  MSGCommTX=COMMPARAMACTIVE;
				  	  	  	  	  		  MSGParameterTX=PARAM13;
				  	  	  	  	  	  }
				  	  	  	  	  	  else DroneTuneStepInt/=10;

			  	  	  	  	  	  	 }break;
			  case Param14TuneScreen:{
				  	  	  	  	  	  if(CurrentCursorPos!=Line1)
				  	  	  	  	  	  {
				  	  	  	  	  		  DroneDataInput.pid_max_yaw-=DroneTuneStepInt;
				  	  	  	  	  		  if(DroneDataInput.pid_max_yaw < MINPIDPARAM)DroneDataInput.pid_max_yaw=MINPIDPARAM;

				  	  	  	  	  		  MSGCommTX=COMMPARAMACTIVE;
				  	  	  	  	  		  MSGParameterTX=PARAM14;
				  	  	  	  	  	  }
				  	  	  	  	  	  else DroneTuneStepInt/=10;

			  	  	  	  	  	  	 }break;
			  case Param15TuneScreen:{
				  	  	  	  	  	  if(CurrentCursorPos!=Line1)
				  	  	  	  	  	  {
				  	  	  	  	  		  DroneDataInput.pid_i_max_yaw-=DroneTuneStepInt;
				  	  	  	  	  		  if(DroneDataInput.pid_i_max_yaw < MINPIDPARAM)DroneDataInput.pid_i_max_yaw=MINPIDPARAM;

				  	  	  	  	  		  MSGCommTX=COMMPARAMACTIVE;
				  	  	  	  	  		  MSGParameterTX=PARAM15;
				  	  	  	  	  	  }
				  	  	  	  	  	  else DroneTuneStepInt/=10;

			  	  	  	  	  	  	 }break;
			  case Param16TuneScreen:{
				  	  	  	  	  	  if(CurrentCursorPos!=Line1)
				  	  	  	  	  	  {
				  	  	  	  	  		  DroneDataInput.maxpitchdegree-=DroneTuneStepInt;
				  	  	  	  	  		  if(DroneDataInput.maxpitchdegree < MINDEGREEPARAM)DroneDataInput.maxpitchdegree=MINDEGREEPARAM;

				  	  	  	  	  		  MSGCommTX=COMMPARAMACTIVE;
				  	  	  	  	  		  MSGParameterTX=PARAM16;
				  	  	  	  	  	  }
				  	  	  	  	  	  else DroneTuneStepInt/=10;

			  	  	  	  	  	  	 }break;
			  case Param17TuneScreen:{
				  	  	  	  	  	  if(CurrentCursorPos!=Line1)
				  	  	  	  	  	  {
				  	  	  	  	  		  DroneDataInput.maxrolldegree-=DroneTuneStepInt;
				  	  	  	  	  		  if(DroneDataInput.maxrolldegree < MINDEGREEPARAM)DroneDataInput.maxrolldegree=MINDEGREEPARAM;

				  	  	  	  	  		  MSGCommTX=COMMPARAMACTIVE;
				  	  	  	  	  		  MSGParameterTX=PARAM17;
				  	  	  	  	  	  }
				  	  	  	  	  	  else DroneTuneStepInt/=10;

			  	  	  	  	  	  	 }break;
			  case Param18TuneScreen:{
				  	  	  	  	  	  if(CurrentCursorPos!=Line1)
				  	  	  	  	  	  {
				  	  	  	  	  		  DroneDataInput.maxyawdegree-=DroneTuneStepInt;
				  	  	  	  	  		  if(DroneDataInput.maxyawdegree < MINDEGREEPARAM)DroneDataInput.maxyawdegree=MINDEGREEPARAM;

				  	  	  	  	  		  MSGCommTX=COMMPARAMACTIVE;
				  	  	  	  	  		  MSGParameterTX=PARAM18;
				  	  	  	  	  	  }
				  	  	  	  	  	  else DroneTuneStepInt/=10;

			  	  	  	  	  	  	 }break;
			  case Param19TuneScreen:{
				  	  	  	  	  	  if(CurrentCursorPos!=Line1)
				  	  	  	  	  	  {
				  	  	  	  	  		  DroneDataInput.minthrottle-=DroneTuneStepInt;
				  	  	  	  	  		  if(DroneDataInput.minthrottle < MINTHROTTLE)DroneDataInput.minthrottle=MINTHROTTLE;

				  	  	  	  	  		  MSGCommTX=COMMPARAMACTIVE;
				  	  	  	  	  		  MSGParameterTX=PARAM19;
				  	  	  	  	  	  }
				  	  	  	  	  	  else DroneTuneStepInt/=10;

			  	  	  	  	  	  	 }break;
			  case Param20TuneScreen:{
				  	  	  	  	  	  if(CurrentCursorPos!=Line1)
				  	  	  	  	  	  {
				  	  	  	  	  		  DroneDataInput.maxthrottle-=DroneTuneStepInt;
				  	  	  	  	  		  if(DroneDataInput.maxthrottle < MINTHROTTLE)DroneDataInput.maxthrottle=MINTHROTTLE;

				  	  	  	  	  		  MSGCommTX=COMMPARAMACTIVE;
				  	  	  	  	  		  MSGParameterTX=PARAM20;
				  	  	  	  	  	  }
				  	  	  	  	  	  else DroneTuneStepInt/=10;

			  	  	  	  	  	     }break;
		  }

		  //zasicenje tunning step
		  if(DroneTuneStep>DRONETUNESTEPMAX)DroneTuneStep=DRONETUNESTEPMAX;
		  if(DroneTuneStep<DRONETUNESTEPMIN)DroneTuneStep=DRONETUNESTEPMIN;

		  if(DroneTuneStepInt>DRONETUNESTEPINTMAX)DroneTuneStepInt=DRONETUNESTEPINTMAX;
		  if(DroneTuneStepInt<DRONETUNESTEPINTMIN)DroneTuneStepInt=DRONETUNESTEPINTMIN;

		  ValueMinus=0;
	  }

	  switch(CurrentScreen)//Display selected screen----------------------------------------------------------------------------------------------------
	  {
	  		case MainScreen:{MainScreenPrint(stringlcdBuffer);}break;
	  		case MenuScreen1:{MenuScreen1Print(stringlcdBuffer,CurrentCursorPos);}break;
	  		case MSGScreen1:{MSGScreen1Print(stringlcdBuffer);}break;
	  		case ButtonScreen1:{ButtonScreen1Print(stringlcdBuffer);}break;
	  		case ButtonScreen2:{ButtonScreen2Print(stringlcdBuffer);}break;
	  		case ButtonScreen3:{ButtonScreen3Print(stringlcdBuffer);}break;
	  		case TestScreen1:{TestScreen1Print(stringlcdBuffer);}break;
	  		case FlashDataScreenRd:{FlashDataScreenRdPrint(stringlcdBuffer);}break;
	  		case FlashDataScreenWr:{FlashDataScreenWrPrint(stringlcdBuffer,CurrentCursorPos);}break;
	  		case CommandScreen1:{CommandScreen1Print(stringlcdBuffer,CurrentCursorPos);}break;
	  	  	case Param1TuneScreen:{Param1TuneScreenPrint(stringlcdBuffer,CurrentCursorPos);}break;
	  	  	case Param2TuneScreen:{Param2TuneScreenPrint(stringlcdBuffer,CurrentCursorPos);}break;
	  	  	case Param3TuneScreen:{Param3TuneScreenPrint(stringlcdBuffer,CurrentCursorPos);}break;
	  	  	case Param4TuneScreen:{Param4TuneScreenPrint(stringlcdBuffer,CurrentCursorPos);}break;
	  	  	case Param5TuneScreen:{Param5TuneScreenPrint(stringlcdBuffer,CurrentCursorPos);}break;
	  	  	case Param6TuneScreen:{Param6TuneScreenPrint(stringlcdBuffer,CurrentCursorPos);}break;
	  	  	case Param7TuneScreen:{Param7TuneScreenPrint(stringlcdBuffer,CurrentCursorPos);}break;
	  	  	case Param8TuneScreen:{Param8TuneScreenPrint(stringlcdBuffer,CurrentCursorPos);}break;
	  	  	case Param9TuneScreen:{Param9TuneScreenPrint(stringlcdBuffer,CurrentCursorPos);}break;
	  	  	case Param10TuneScreen:{Param10TuneScreenPrint(stringlcdBuffer,CurrentCursorPos);}break;
	  	  	case Param11TuneScreen:{Param11TuneScreenPrint(stringlcdBuffer,CurrentCursorPos);}break;
	  	  	case Param12TuneScreen:{Param12TuneScreenPrint(stringlcdBuffer,CurrentCursorPos);}break;
		  	case Param13TuneScreen:{Param13TuneScreenPrint(stringlcdBuffer,CurrentCursorPos);}break;
		  	case Param14TuneScreen:{Param14TuneScreenPrint(stringlcdBuffer,CurrentCursorPos);}break;
			case Param15TuneScreen:{Param15TuneScreenPrint(stringlcdBuffer,CurrentCursorPos);}break;
			case Param16TuneScreen:{Param16TuneScreenPrint(stringlcdBuffer,CurrentCursorPos);}break;
			case Param17TuneScreen:{Param17TuneScreenPrint(stringlcdBuffer,CurrentCursorPos);}break;
			case Param18TuneScreen:{Param18TuneScreenPrint(stringlcdBuffer,CurrentCursorPos);}break;
			case Param19TuneScreen:{Param19TuneScreenPrint(stringlcdBuffer,CurrentCursorPos);}break;
			case Param20TuneScreen:{Param20TuneScreenPrint(stringlcdBuffer,CurrentCursorPos);}break;
	  }

	  //test1=DWT->CYCCNT;
	  //test2=DWT->CYCCNT-test1;

    /* USER CODE END WHILE */

  }
}

void SystemClock_Config(void)
{
  RCC_OscInitTypeDef RCC_OscInitStruct = {0};
  RCC_ClkInitTypeDef RCC_ClkInitStruct = {0};
  RCC_PeriphCLKInitTypeDef PeriphClkInit = {0};

  /** Initializes the CPU, AHB and APB busses clocks
  */
  RCC_OscInitStruct.OscillatorType = RCC_OSCILLATORTYPE_HSE;
  RCC_OscInitStruct.HSEState = RCC_HSE_ON;
  RCC_OscInitStruct.HSEPredivValue = RCC_HSE_PREDIV_DIV1;
  RCC_OscInitStruct.HSIState = RCC_HSI_ON;
  RCC_OscInitStruct.PLL.PLLState = RCC_PLL_ON;
  RCC_OscInitStruct.PLL.PLLSource = RCC_PLLSOURCE_HSE;
  RCC_OscInitStruct.PLL.PLLMUL = RCC_PLL_MUL9;
  if (HAL_RCC_OscConfig(&RCC_OscInitStruct) != HAL_OK)
  {
    Error_Handler();
  }
  /** Initializes the CPU, AHB and APB busses clocks
  */
  RCC_ClkInitStruct.ClockType = RCC_CLOCKTYPE_HCLK|RCC_CLOCKTYPE_SYSCLK
                              |RCC_CLOCKTYPE_PCLK1|RCC_CLOCKTYPE_PCLK2;
  RCC_ClkInitStruct.SYSCLKSource = RCC_SYSCLKSOURCE_PLLCLK;
  RCC_ClkInitStruct.AHBCLKDivider = RCC_SYSCLK_DIV1;
  RCC_ClkInitStruct.APB1CLKDivider = RCC_HCLK_DIV2;
  RCC_ClkInitStruct.APB2CLKDivider = RCC_HCLK_DIV1;

  if (HAL_RCC_ClockConfig(&RCC_ClkInitStruct, FLASH_LATENCY_2) != HAL_OK)
  {
    Error_Handler();
  }
  PeriphClkInit.PeriphClockSelection = RCC_PERIPHCLK_ADC;
  PeriphClkInit.AdcClockSelection = RCC_ADCPCLK2_DIV6;
  if (HAL_RCCEx_PeriphCLKConfig(&PeriphClkInit) != HAL_OK)
  {
    Error_Handler();
  }
}

static void MX_ADC1_Init(void)
{

  ADC_ChannelConfTypeDef sConfig = {0};

  /** Common config
  */
  hadc1.Instance = ADC1;
  hadc1.Init.ScanConvMode = ADC_SCAN_ENABLE;
  hadc1.Init.ContinuousConvMode = ENABLE;
  hadc1.Init.DiscontinuousConvMode = DISABLE;
  hadc1.Init.ExternalTrigConv = ADC_SOFTWARE_START;
  hadc1.Init.DataAlign = ADC_DATAALIGN_RIGHT;
  hadc1.Init.NbrOfConversion = 7;
  if (HAL_ADC_Init(&hadc1) != HAL_OK)
  {
    Error_Handler();
  }
  /** Configure Regular Channel
  */
  sConfig.Channel = ADC_CHANNEL_0;
  sConfig.Rank = ADC_REGULAR_RANK_1;
  sConfig.SamplingTime = ADC_SAMPLETIME_13CYCLES_5;
  if (HAL_ADC_ConfigChannel(&hadc1, &sConfig) != HAL_OK)
  {
    Error_Handler();
  }
  /** Configure Regular Channel
  */
  sConfig.Channel = ADC_CHANNEL_1;
  sConfig.Rank = ADC_REGULAR_RANK_2;
  if (HAL_ADC_ConfigChannel(&hadc1, &sConfig) != HAL_OK)
  {
    Error_Handler();
  }
  /** Configure Regular Channel
  */
  sConfig.Channel = ADC_CHANNEL_2;
  sConfig.Rank = ADC_REGULAR_RANK_3;
  if (HAL_ADC_ConfigChannel(&hadc1, &sConfig) != HAL_OK)
  {
    Error_Handler();
  }
  /** Configure Regular Channel
  */
  sConfig.Channel = ADC_CHANNEL_3;
  sConfig.Rank = ADC_REGULAR_RANK_4;
  if (HAL_ADC_ConfigChannel(&hadc1, &sConfig) != HAL_OK)
  {
    Error_Handler();
  }
  /** Configure Regular Channel
  */
  sConfig.Channel = ADC_CHANNEL_4;
  sConfig.Rank = ADC_REGULAR_RANK_5;
  if (HAL_ADC_ConfigChannel(&hadc1, &sConfig) != HAL_OK)
  {
    Error_Handler();
  }
  /** Configure Regular Channel
  */
  sConfig.Channel = ADC_CHANNEL_8;
  sConfig.Rank = ADC_REGULAR_RANK_6;
  if (HAL_ADC_ConfigChannel(&hadc1, &sConfig) != HAL_OK)
  {
    Error_Handler();
  }
  /** Configure Regular Channel
  */
  sConfig.Channel = ADC_CHANNEL_9;
  sConfig.Rank = ADC_REGULAR_RANK_7;
  if (HAL_ADC_ConfigChannel(&hadc1, &sConfig) != HAL_OK)
  {
    Error_Handler();
  }

}

static void MX_I2C2_Init(void)
{

  hi2c2.Instance = I2C2;
  hi2c2.Init.ClockSpeed = 100000;
  hi2c2.Init.DutyCycle = I2C_DUTYCYCLE_2;
  hi2c2.Init.OwnAddress1 = 0;
  hi2c2.Init.AddressingMode = I2C_ADDRESSINGMODE_7BIT;
  hi2c2.Init.DualAddressMode = I2C_DUALADDRESS_DISABLE;
  hi2c2.Init.OwnAddress2 = 0;
  hi2c2.Init.GeneralCallMode = I2C_GENERALCALL_DISABLE;
  hi2c2.Init.NoStretchMode = I2C_NOSTRETCH_DISABLE;
  if (HAL_I2C_Init(&hi2c2) != HAL_OK)
  {
    Error_Handler();
  }

}

static void MX_SPI1_Init(void)
{

  /* SPI1 parameter configuration*/
  hspi1.Instance = SPI1;
  hspi1.Init.Mode = SPI_MODE_MASTER;
  hspi1.Init.Direction = SPI_DIRECTION_2LINES;
  hspi1.Init.DataSize = SPI_DATASIZE_8BIT;
  hspi1.Init.CLKPolarity = SPI_POLARITY_LOW;
  hspi1.Init.CLKPhase = SPI_PHASE_1EDGE;
  hspi1.Init.NSS = SPI_NSS_SOFT;
  hspi1.Init.BaudRatePrescaler = SPI_BAUDRATEPRESCALER_8;
  hspi1.Init.FirstBit = SPI_FIRSTBIT_MSB;
  hspi1.Init.TIMode = SPI_TIMODE_DISABLE;
  hspi1.Init.CRCCalculation = SPI_CRCCALCULATION_ENABLE;
  hspi1.Init.CRCPolynomial = 10;
  if (HAL_SPI_Init(&hspi1) != HAL_OK)
  {
    Error_Handler();
  }

}

static void MX_TIM4_Init(void)
{

  TIM_MasterConfigTypeDef sMasterConfig = {0};
  TIM_OC_InitTypeDef sConfigOC = {0};

  htim4.Instance = TIM4;
  htim4.Init.Prescaler = 9;
  htim4.Init.CounterMode = TIM_COUNTERMODE_UP;
  htim4.Init.Period = 5000;
  htim4.Init.ClockDivision = TIM_CLOCKDIVISION_DIV1;
  htim4.Init.AutoReloadPreload = TIM_AUTORELOAD_PRELOAD_DISABLE;
  if (HAL_TIM_PWM_Init(&htim4) != HAL_OK)
  {
    Error_Handler();
  }
  sMasterConfig.MasterOutputTrigger = TIM_TRGO_RESET;
  sMasterConfig.MasterSlaveMode = TIM_MASTERSLAVEMODE_DISABLE;
  if (HAL_TIMEx_MasterConfigSynchronization(&htim4, &sMasterConfig) != HAL_OK)
  {
    Error_Handler();
  }
  sConfigOC.OCMode = TIM_OCMODE_PWM1;
  sConfigOC.Pulse = 800;
  sConfigOC.OCPolarity = TIM_OCPOLARITY_HIGH;
  sConfigOC.OCFastMode = TIM_OCFAST_DISABLE;
  if (HAL_TIM_PWM_ConfigChannel(&htim4, &sConfigOC, TIM_CHANNEL_2) != HAL_OK)
  {
    Error_Handler();
  }
  HAL_TIM_MspPostInit(&htim4);

}

static void MX_DMA_Init(void)
{

  /* DMA controller clock enable */
  __HAL_RCC_DMA1_CLK_ENABLE();

  /* DMA interrupt init */
  /* DMA1_Channel1_IRQn interrupt configuration */
  HAL_NVIC_SetPriority(DMA1_Channel1_IRQn, 0, 0);
  HAL_NVIC_EnableIRQ(DMA1_Channel1_IRQn);

}

static void MX_GPIO_Init(void)
{
  GPIO_InitTypeDef GPIO_InitStruct = {0};

  /* GPIO Ports Clock Enable */
  __HAL_RCC_GPIOC_CLK_ENABLE();
  __HAL_RCC_GPIOD_CLK_ENABLE();
  __HAL_RCC_GPIOA_CLK_ENABLE();
  __HAL_RCC_GPIOB_CLK_ENABLE();

  /*Configure GPIO pin Output Level */
  HAL_GPIO_WritePin(LED2_GPIO_Port, LED2_Pin, GPIO_PIN_RESET);

  /*Configure GPIO pin Output Level */
  HAL_GPIO_WritePin(GPIOB, LCD_RST_Pin|LCD_CLK_Pin|LCD_CE_Pin|LCD_DATA_Pin
                          |LED3_Pin|SPI_NR24_CSN_Pin|LED4_Pin|LED1_Pin, GPIO_PIN_RESET);

  /*Configure GPIO pin Output Level */
  HAL_GPIO_WritePin(GPIOA, LCD_COMM_Pin|SPI_NR24_CE_Pin, GPIO_PIN_RESET);

  /*Configure GPIO pin : LED2_Pin */
  GPIO_InitStruct.Pin = LED2_Pin;
  GPIO_InitStruct.Mode = GPIO_MODE_OUTPUT_PP;
  GPIO_InitStruct.Pull = GPIO_NOPULL;
  GPIO_InitStruct.Speed = GPIO_SPEED_FREQ_LOW;
  HAL_GPIO_Init(LED2_GPIO_Port, &GPIO_InitStruct);

  /*Configure GPIO pin : SPI_NR24_IRQ_Pin */
  GPIO_InitStruct.Pin = SPI_NR24_IRQ_Pin;
  GPIO_InitStruct.Mode = GPIO_MODE_INPUT;
  GPIO_InitStruct.Pull = GPIO_NOPULL;
  HAL_GPIO_Init(SPI_NR24_IRQ_GPIO_Port, &GPIO_InitStruct);

  /*Configure GPIO pins : LCD_RST_Pin LCD_CE_Pin LED3_Pin SPI_NR24_CSN_Pin
                           LED4_Pin LED1_Pin */
  GPIO_InitStruct.Pin = LCD_RST_Pin|LCD_CE_Pin|LED3_Pin|SPI_NR24_CSN_Pin
                          |LED4_Pin|LED1_Pin;
  GPIO_InitStruct.Mode = GPIO_MODE_OUTPUT_PP;
  GPIO_InitStruct.Pull = GPIO_NOPULL;
  GPIO_InitStruct.Speed = GPIO_SPEED_FREQ_LOW;
  HAL_GPIO_Init(GPIOB, &GPIO_InitStruct);

  /*Configure GPIO pins : LCD_CLK_Pin LCD_DATA_Pin */
  GPIO_InitStruct.Pin = LCD_CLK_Pin|LCD_DATA_Pin;
  GPIO_InitStruct.Mode = GPIO_MODE_OUTPUT_PP;
  GPIO_InitStruct.Pull = GPIO_NOPULL;
  GPIO_InitStruct.Speed = GPIO_SPEED_FREQ_HIGH;
  HAL_GPIO_Init(GPIOB, &GPIO_InitStruct);

  /*Configure GPIO pin : LCD_COMM_Pin */
  GPIO_InitStruct.Pin = LCD_COMM_Pin;
  GPIO_InitStruct.Mode = GPIO_MODE_OUTPUT_PP;
  GPIO_InitStruct.Pull = GPIO_NOPULL;
  GPIO_InitStruct.Speed = GPIO_SPEED_FREQ_HIGH;
  HAL_GPIO_Init(LCD_COMM_GPIO_Port, &GPIO_InitStruct);

  /*Configure GPIO pins : TOGG1_Pin TOGG2_Pin TOGG3_Pin TOGG4_Pin */
  GPIO_InitStruct.Pin = TOGG1_Pin|TOGG2_Pin|TOGG3_Pin|TOGG4_Pin;
  GPIO_InitStruct.Mode = GPIO_MODE_INPUT;
  GPIO_InitStruct.Pull = GPIO_PULLUP;
  HAL_GPIO_Init(GPIOA, &GPIO_InitStruct);

  /*Configure GPIO pin : SPI_NR24_CE_Pin */
  GPIO_InitStruct.Pin = SPI_NR24_CE_Pin;
  GPIO_InitStruct.Mode = GPIO_MODE_OUTPUT_PP;
  GPIO_InitStruct.Pull = GPIO_NOPULL;
  GPIO_InitStruct.Speed = GPIO_SPEED_FREQ_LOW;
  HAL_GPIO_Init(SPI_NR24_CE_GPIO_Port, &GPIO_InitStruct);

  /*Configure GPIO pins : TOGG5_Pin TOGG6_Pin */
  GPIO_InitStruct.Pin = TOGG5_Pin|TOGG6_Pin;
  GPIO_InitStruct.Mode = GPIO_MODE_INPUT;
  GPIO_InitStruct.Pull = GPIO_PULLUP;
  HAL_GPIO_Init(GPIOB, &GPIO_InitStruct);

}

/* USER CODE BEGIN 4 */

//Write Data into Flash starting from given address
void WriteFlashData(uint32_t StartAddr, struct FlashDatastruct *p)
{
	FLASH_EraseInitTypeDef EraseInitStruct;

	uint32_t PageError;

	EraseInitStruct.TypeErase   = FLASH_TYPEERASE_PAGES;
	EraseInitStruct.PageAddress = StartAddr;
	EraseInitStruct.NbPages     = 1;

	HAL_FLASH_Unlock();

	//FLASH_PageErase(0x800FC00); //doesn't handle all registers PER regiser in CR is not cleared

	HAL_FLASHEx_Erase(&EraseInitStruct, &PageError);

	HAL_FLASH_Program(FLASH_TYPEPROGRAM_WORD,StartAddr, p->controlData);
	HAL_FLASH_Program(FLASH_TYPEPROGRAM_WORD,StartAddr+4, p->LCD_contrast);
	HAL_FLASH_Program(FLASH_TYPEPROGRAM_WORD,StartAddr+8, p->LjoyXtrim);
	HAL_FLASH_Program(FLASH_TYPEPROGRAM_WORD,StartAddr+12, p->LjoyYtrim);
	HAL_FLASH_Program(FLASH_TYPEPROGRAM_WORD,StartAddr+16, p->RjoyXtrim);
	HAL_FLASH_Program(FLASH_TYPEPROGRAM_WORD,StartAddr+20, p->RjoyYtrim);

	HAL_FLASH_Lock();
}

void EraseFlashData(uint32_t StartAddr)
{
	FLASH_EraseInitTypeDef EraseInitStruct;

	uint32_t PageError;

	EraseInitStruct.TypeErase   = FLASH_TYPEERASE_PAGES;
	EraseInitStruct.PageAddress = StartAddr;
	EraseInitStruct.NbPages     = 1;

	HAL_FLASH_Unlock();

	//FLASH_PageErase(0x800FC00); //doesn't handle all registers PER regiser in CR is not cleared

	HAL_FLASHEx_Erase(&EraseInitStruct, &PageError);

	HAL_FLASH_Lock();
}

//Check if Data on given address matches control word
uint32_t CheckFlashData(uint32_t StartAddr)
{
	return *(( uint32_t *) (StartAddr) );
}

//Read Data from Flash
void ReadFlashData(uint32_t StartAddr, struct FlashDatastruct *p)
{
	p->controlData= *(( uint32_t *) (StartAddr) );
	p->LCD_contrast=*(( uint32_t *) (StartAddr+4) );
	p->LjoyXtrim=*(( uint32_t *) (StartAddr+8) );
	p->LjoyYtrim=*(( uint32_t *) (StartAddr+12) );
	p->RjoyXtrim=*(( uint32_t *) (StartAddr+16) );
	p->RjoyYtrim=*(( uint32_t *) (StartAddr+20) );
}

/* USER CODE END 4 */

void Error_Handler(void)
{
}

/************************ (C) COPYRIGHT STMicroelectronics *****END OF FILE****/
